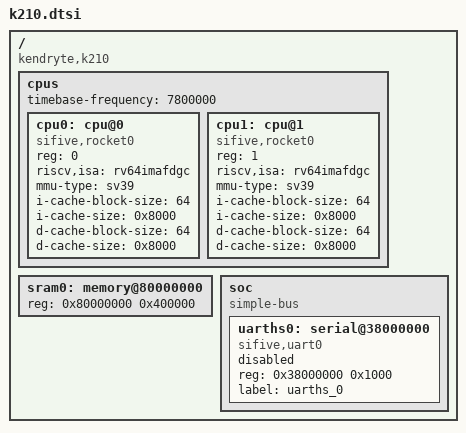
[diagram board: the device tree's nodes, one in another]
// SPDX-License-Identifier: GPL-2.0+
/*
 * Copyright (C) 2019-20 Sean Anderson <seanga2@gmail.com>
 */

/ {
	/*
	 * Although the K210 is a 64-bit CPU, the address bus is only 32-bits
	 * wide, and the upper half of all addresses is ignored.
	 */
	#address-cells = <1>;
	#size-cells = <1>;
	compatible = "kendryte,k210";

	cpus {
		#address-cells = <1>;
		#size-cells = <0>;
		timebase-frequency = <7800000>;
		cpu0: cpu@0 {
			device_type = "cpu";
			compatible = "sifive,rocket0", "riscv";
			reg = <0>;
			riscv,isa = "rv64imafdgc";
			mmu-type = "sv39";
			i-cache-block-size = <64>;
			i-cache-size = <0x8000>;
			d-cache-block-size = <64>;
			d-cache-size = <0x8000>;
		};
		cpu1: cpu@1 {
			device_type = "cpu";
			compatible = "sifive,rocket0", "riscv";
			reg = <1>;
			riscv,isa = "rv64imafdgc";
			mmu-type = "sv39";
			i-cache-block-size = <64>;
			i-cache-size = <0x8000>;
			d-cache-block-size = <64>;
			d-cache-size = <0x8000>;
		};
	};

	sram0: memory@80000000 {
		device_type = "memory";
		reg = <0x80000000 0x400000>;
	};

	soc {
		#address-cells = <1>;
		#size-cells = <1>;
		compatible = "simple-bus";
		ranges;

		uarths0: serial@38000000 {
			compatible = "sifive,uart0";
			reg = <0x38000000 0x1000>;
			label = "uarths_0";
			status = "disabled";
		};
	};
};
